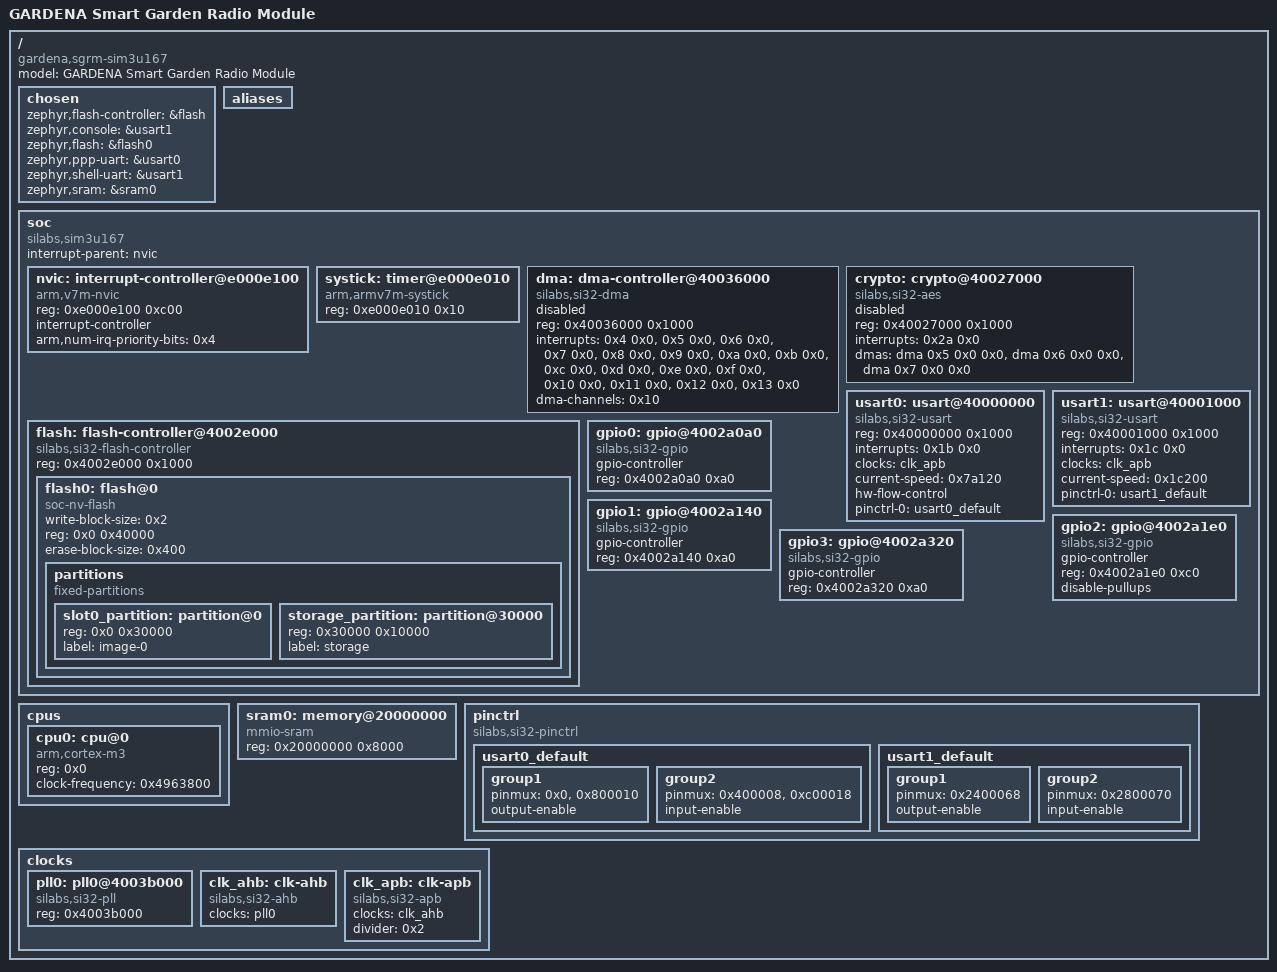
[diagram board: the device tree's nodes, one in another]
/dts-v1/;

/* node '/' defined in zephyr/dts/common/skeleton.dtsi:9 */
/ {
	#address-cells = < 0x1 >;                    /* in zephyr/dts/common/skeleton.dtsi:10 */
	#size-cells = < 0x1 >;                       /* in zephyr/dts/common/skeleton.dtsi:11 */
	model = "GARDENA Smart Garden Radio Module"; /* in zephyr/boards/gardena/sgrm/sgrm.dts:12 */
	compatible = "gardena,sgrm-sim3u167",
	             "silabs,sim3u167",
	             "silabs,sim3u";                 /* in zephyr/boards/gardena/sgrm/sgrm.dts:13 */

	/* node '/chosen' defined in zephyr/dts/common/skeleton.dtsi:13 */
	chosen {
		zephyr,flash-controller = &flash; /* in zephyr/dts/arm/silabs/sim3u.dtsi:13 */
		zephyr,console = &usart1;         /* in zephyr/boards/gardena/sgrm/sgrm.dts:16 */
		zephyr,flash = &flash0;           /* in zephyr/boards/gardena/sgrm/sgrm.dts:17 */
		zephyr,ppp-uart = &usart0;        /* in zephyr/boards/gardena/sgrm/sgrm.dts:18 */
		zephyr,shell-uart = &usart1;      /* in zephyr/boards/gardena/sgrm/sgrm.dts:19 */
		zephyr,sram = &sram0;             /* in zephyr/boards/gardena/sgrm/sgrm.dts:20 */
	};

	/* node '/aliases' defined in zephyr/dts/common/skeleton.dtsi:15 */
	aliases {
	};

	/* node '/soc' defined in zephyr/dts/arm/armv7-m.dtsi:6 */
	soc {
		#address-cells = < 0x1 >;       /* in zephyr/dts/arm/armv7-m.dtsi:7 */
		#size-cells = < 0x1 >;          /* in zephyr/dts/arm/armv7-m.dtsi:8 */
		interrupt-parent = < &nvic >;   /* in zephyr/dts/arm/armv7-m.dtsi:10 */
		ranges;                         /* in zephyr/dts/arm/armv7-m.dtsi:11 */
		compatible = "silabs,sim3u167",
		             "silabs,sim3u",
		             "silabs,sim3",
		             "simple-bus";      /* in zephyr/dts/arm/silabs/sim3u167.dtsi:12 */

		/* node '/soc/interrupt-controller@e000e100' defined in zephyr/dts/arm/armv7-m.dtsi:13 */
		nvic: interrupt-controller@e000e100 {
			#address-cells = < 0x1 >;            /* in zephyr/dts/arm/armv7-m.dtsi:14 */
			compatible = "arm,v7m-nvic";         /* in zephyr/dts/arm/armv7-m.dtsi:15 */
			reg = < 0xe000e100 0xc00 >;          /* in zephyr/dts/arm/armv7-m.dtsi:16 */
			interrupt-controller;                /* in zephyr/dts/arm/armv7-m.dtsi:17 */
			#interrupt-cells = < 0x2 >;          /* in zephyr/dts/arm/armv7-m.dtsi:18 */
			arm,num-irq-priority-bits = < 0x4 >; /* in zephyr/dts/arm/silabs/sim3u.dtsi:147 */
			phandle = < 0x1 >;                   /* in zephyr/dts/arm/armv7-m.dtsi:10 */
		};

		/* node '/soc/timer@e000e010' defined in zephyr/dts/arm/armv7-m.dtsi:21 */
		systick: timer@e000e010 {
			compatible = "arm,armv7m-systick"; /* in zephyr/dts/arm/armv7-m.dtsi:22 */
			reg = < 0xe000e010 0x10 >;         /* in zephyr/dts/arm/armv7-m.dtsi:23 */
		};

		/* node '/soc/dma-controller@40036000' defined in zephyr/dts/arm/silabs/sim3u.dtsi:64 */
		dma: dma-controller@40036000 {
			compatible = "silabs,si32-dma"; /* in zephyr/dts/arm/silabs/sim3u.dtsi:65 */
			reg = < 0x40036000 0x1000 >;    /* in zephyr/dts/arm/silabs/sim3u.dtsi:66 */
			interrupts = < 0x4 0x0 >,
			             < 0x5 0x0 >,
			             < 0x6 0x0 >,
			             < 0x7 0x0 >,
			             < 0x8 0x0 >,
			             < 0x9 0x0 >,
			             < 0xa 0x0 >,
			             < 0xb 0x0 >,
			             < 0xc 0x0 >,
			             < 0xd 0x0 >,
			             < 0xe 0x0 >,
			             < 0xf 0x0 >,
			             < 0x10 0x0 >,
			             < 0x11 0x0 >,
			             < 0x12 0x0 >,
			             < 0x13 0x0 >;      /* in zephyr/dts/arm/silabs/sim3u.dtsi:67 */
			dma-channels = < 0x10 >;        /* in zephyr/dts/arm/silabs/sim3u.dtsi:71 */
			#dma-cells = < 0x3 >;           /* in zephyr/dts/arm/silabs/sim3u.dtsi:72 */
			status = "disabled";            /* in zephyr/dts/arm/silabs/sim3u.dtsi:73 */
			phandle = < 0x2 >;              /* in zephyr/dts/arm/silabs/sim3u.dtsi:80 */
		};

		/* node '/soc/crypto@40027000' defined in zephyr/dts/arm/silabs/sim3u.dtsi:76 */
		crypto: crypto@40027000 {
			compatible = "silabs,si32-aes"; /* in zephyr/dts/arm/silabs/sim3u.dtsi:77 */
			reg = < 0x40027000 0x1000 >;    /* in zephyr/dts/arm/silabs/sim3u.dtsi:78 */
			interrupts = < 0x2a 0x0 >;      /* in zephyr/dts/arm/silabs/sim3u.dtsi:79 */
			dmas = < &dma 0x5 0x0 0x0 >,
			       < &dma 0x6 0x0 0x0 >,
			       < &dma 0x7 0x0 0x0 >;    /* in zephyr/dts/arm/silabs/sim3u.dtsi:80 */
			dma-names = "tx",
			            "rx",
			            "xor";              /* in zephyr/dts/arm/silabs/sim3u.dtsi:83 */
			status = "disabled";            /* in zephyr/dts/arm/silabs/sim3u.dtsi:84 */
		};

		/* node '/soc/flash-controller@4002e000' defined in zephyr/dts/arm/silabs/sim3u.dtsi:87 */
		flash: flash-controller@4002e000 {
			compatible = "silabs,si32-flash-controller"; /* in zephyr/dts/arm/silabs/sim3u.dtsi:88 */
			reg = < 0x4002e000 0x1000 >;                 /* in zephyr/dts/arm/silabs/sim3u.dtsi:89 */
			#address-cells = < 0x1 >;                    /* in zephyr/dts/arm/silabs/sim3u.dtsi:91 */
			#size-cells = < 0x1 >;                       /* in zephyr/dts/arm/silabs/sim3u.dtsi:92 */

			/* node '/soc/flash-controller@4002e000/flash@0' defined in zephyr/dts/arm/silabs/sim3u.dtsi:94 */
			flash0: flash@0 {
				compatible = "soc-nv-flash";  /* in zephyr/dts/arm/silabs/sim3u.dtsi:95 */
				write-block-size = < 0x2 >;   /* in zephyr/dts/arm/silabs/sim3u.dtsi:96 */
				reg = < 0x0 0x40000 >;        /* in zephyr/dts/arm/silabs/sim3u167.dtsi:17 */
				erase-block-size = < 0x400 >; /* in zephyr/dts/arm/silabs/sim3u167.dtsi:18 */
				status = "okay";              /* in zephyr/boards/gardena/sgrm/sgrm.dts:75 */

				/* node '/soc/flash-controller@4002e000/flash@0/partitions' defined in zephyr/boards/gardena/sgrm/sgrm.dts:77 */
				partitions {
					compatible = "fixed-partitions"; /* in zephyr/boards/gardena/sgrm/sgrm.dts:78 */
					#address-cells = < 0x1 >;        /* in zephyr/boards/gardena/sgrm/sgrm.dts:79 */
					#size-cells = < 0x1 >;           /* in zephyr/boards/gardena/sgrm/sgrm.dts:80 */

					/* node '/soc/flash-controller@4002e000/flash@0/partitions/partition@0' defined in zephyr/boards/gardena/sgrm/sgrm.dts:82 */
					slot0_partition: partition@0 {
						reg = < 0x0 0x30000 >; /* in zephyr/boards/gardena/sgrm/sgrm.dts:83 */
						label = "image-0";     /* in zephyr/boards/gardena/sgrm/sgrm.dts:84 */
					};

					/* node '/soc/flash-controller@4002e000/flash@0/partitions/partition@30000' defined in zephyr/boards/gardena/sgrm/sgrm.dts:87 */
					storage_partition: partition@30000 {
						reg = < 0x30000 0x10000 >; /* in zephyr/boards/gardena/sgrm/sgrm.dts:88 */
						label = "storage";         /* in zephyr/boards/gardena/sgrm/sgrm.dts:89 */
					};
				};
			};
		};

		/* node '/soc/usart@40000000' defined in zephyr/dts/arm/silabs/sim3u.dtsi:100 */
		usart0: usart@40000000 {
			compatible = "silabs,si32-usart"; /* in zephyr/dts/arm/silabs/sim3u.dtsi:101 */
			reg = < 0x40000000 0x1000 >;      /* in zephyr/dts/arm/silabs/sim3u.dtsi:102 */
			interrupts = < 0x1b 0x0 >;        /* in zephyr/dts/arm/silabs/sim3u.dtsi:103 */
			clocks = < &clk_apb >;            /* in zephyr/dts/arm/silabs/sim3u.dtsi:104 */
			current-speed = < 0x7a120 >;      /* in zephyr/boards/gardena/sgrm/sgrm.dts:43 */
			hw-flow-control;                  /* in zephyr/boards/gardena/sgrm/sgrm.dts:44 */
			pinctrl-0 = < &usart0_default >;  /* in zephyr/boards/gardena/sgrm/sgrm.dts:45 */
			pinctrl-names = "default";        /* in zephyr/boards/gardena/sgrm/sgrm.dts:46 */
			status = "okay";                  /* in zephyr/boards/gardena/sgrm/sgrm.dts:47 */
		};

		/* node '/soc/usart@40001000' defined in zephyr/dts/arm/silabs/sim3u.dtsi:108 */
		usart1: usart@40001000 {
			compatible = "silabs,si32-usart"; /* in zephyr/dts/arm/silabs/sim3u.dtsi:109 */
			reg = < 0x40001000 0x1000 >;      /* in zephyr/dts/arm/silabs/sim3u.dtsi:110 */
			interrupts = < 0x1c 0x0 >;        /* in zephyr/dts/arm/silabs/sim3u.dtsi:111 */
			clocks = < &clk_apb >;            /* in zephyr/dts/arm/silabs/sim3u.dtsi:112 */
			current-speed = < 0x1c200 >;      /* in zephyr/boards/gardena/sgrm/sgrm.dts:51 */
			pinctrl-0 = < &usart1_default >;  /* in zephyr/boards/gardena/sgrm/sgrm.dts:52 */
			pinctrl-names = "default";        /* in zephyr/boards/gardena/sgrm/sgrm.dts:53 */
			status = "okay";                  /* in zephyr/boards/gardena/sgrm/sgrm.dts:54 */
		};

		/* node '/soc/gpio@4002a0a0' defined in zephyr/dts/arm/silabs/sim3u.dtsi:116 */
		gpio0: gpio@4002a0a0 {
			compatible = "silabs,si32-gpio"; /* in zephyr/dts/arm/silabs/sim3u.dtsi:117 */
			gpio-controller;                 /* in zephyr/dts/arm/silabs/sim3u.dtsi:118 */
			#gpio-cells = < 0x2 >;           /* in zephyr/dts/arm/silabs/sim3u.dtsi:119 */
			reg = < 0x4002a0a0 0xa0 >;       /* in zephyr/dts/arm/silabs/sim3u.dtsi:120 */
			status = "okay";                 /* in zephyr/boards/gardena/sgrm/sgrm.dts:58 */
		};

		/* node '/soc/gpio@4002a140' defined in zephyr/dts/arm/silabs/sim3u.dtsi:123 */
		gpio1: gpio@4002a140 {
			compatible = "silabs,si32-gpio"; /* in zephyr/dts/arm/silabs/sim3u.dtsi:124 */
			gpio-controller;                 /* in zephyr/dts/arm/silabs/sim3u.dtsi:125 */
			#gpio-cells = < 0x2 >;           /* in zephyr/dts/arm/silabs/sim3u.dtsi:126 */
			reg = < 0x4002a140 0xa0 >;       /* in zephyr/dts/arm/silabs/sim3u.dtsi:127 */
			status = "okay";                 /* in zephyr/boards/gardena/sgrm/sgrm.dts:62 */
		};

		/* node '/soc/gpio@4002a1e0' defined in zephyr/dts/arm/silabs/sim3u.dtsi:130 */
		gpio2: gpio@4002a1e0 {
			compatible = "silabs,si32-gpio"; /* in zephyr/dts/arm/silabs/sim3u.dtsi:131 */
			gpio-controller;                 /* in zephyr/dts/arm/silabs/sim3u.dtsi:132 */
			#gpio-cells = < 0x2 >;           /* in zephyr/dts/arm/silabs/sim3u.dtsi:133 */
			reg = < 0x4002a1e0 0xc0 >;       /* in zephyr/dts/arm/silabs/sim3u.dtsi:134 */
			disable-pullups;                 /* in zephyr/boards/gardena/sgrm/sgrm.dts:66 */
			status = "okay";                 /* in zephyr/boards/gardena/sgrm/sgrm.dts:67 */
		};

		/* node '/soc/gpio@4002a320' defined in zephyr/dts/arm/silabs/sim3u.dtsi:137 */
		gpio3: gpio@4002a320 {
			compatible = "silabs,si32-gpio"; /* in zephyr/dts/arm/silabs/sim3u.dtsi:138 */
			gpio-controller;                 /* in zephyr/dts/arm/silabs/sim3u.dtsi:139 */
			#gpio-cells = < 0x2 >;           /* in zephyr/dts/arm/silabs/sim3u.dtsi:140 */
			reg = < 0x4002a320 0xa0 >;       /* in zephyr/dts/arm/silabs/sim3u.dtsi:141 */
			status = "okay";                 /* in zephyr/boards/gardena/sgrm/sgrm.dts:71 */
		};
	};

	/* node '/cpus' defined in zephyr/dts/arm/silabs/sim3u.dtsi:16 */
	cpus {
		#address-cells = < 0x1 >; /* in zephyr/dts/arm/silabs/sim3u.dtsi:17 */
		#size-cells = < 0x0 >;    /* in zephyr/dts/arm/silabs/sim3u.dtsi:18 */

		/* node '/cpus/cpu@0' defined in zephyr/dts/arm/silabs/sim3u.dtsi:20 */
		cpu0: cpu@0 {
			compatible = "arm,cortex-m3";    /* in zephyr/dts/arm/silabs/sim3u.dtsi:21 */
			device_type = "cpu";             /* in zephyr/dts/arm/silabs/sim3u.dtsi:22 */
			reg = < 0x0 >;                   /* in zephyr/dts/arm/silabs/sim3u.dtsi:24 */
			clock-frequency = < 0x4963800 >; /* in zephyr/boards/gardena/sgrm/sgrm.dts:25 */
		};
	};

	/* node '/memory@20000000' defined in zephyr/dts/arm/silabs/sim3u.dtsi:28 */
	sram0: memory@20000000 {
		compatible = "mmio-sram";    /* in zephyr/dts/arm/silabs/sim3u.dtsi:29 */
		reg = < 0x20000000 0x8000 >; /* in zephyr/dts/arm/silabs/sim3u167.dtsi:22 */
	};

	/* node '/pinctrl' defined in zephyr/dts/arm/silabs/sim3u.dtsi:32 */
	pinctrl: pinctrl {
		compatible = "silabs,si32-pinctrl"; /* in zephyr/dts/arm/silabs/sim3u.dtsi:33 */
		status = "okay";                    /* in zephyr/dts/arm/silabs/sim3u.dtsi:34 */

		/* node '/pinctrl/usart0_default' defined in zephyr/boards/gardena/sgrm/sgrm-pinctrl.dtsi:10 */
		usart0_default: usart0_default {
			phandle = < 0x4 >; /* in zephyr/boards/gardena/sgrm/sgrm.dts:45 */

			/* node '/pinctrl/usart0_default/group1' defined in zephyr/boards/gardena/sgrm/sgrm-pinctrl.dtsi:11 */
			group1 {
				pinmux = < 0x0 >,
				         < 0x800010 >; /* in zephyr/boards/gardena/sgrm/sgrm-pinctrl.dtsi:12 */
				output-enable;         /* in zephyr/boards/gardena/sgrm/sgrm-pinctrl.dtsi:14 */
			};

			/* node '/pinctrl/usart0_default/group2' defined in zephyr/boards/gardena/sgrm/sgrm-pinctrl.dtsi:17 */
			group2 {
				pinmux = < 0x400008 >,
				         < 0xc00018 >; /* in zephyr/boards/gardena/sgrm/sgrm-pinctrl.dtsi:18 */
				input-enable;          /* in zephyr/boards/gardena/sgrm/sgrm-pinctrl.dtsi:20 */
			};
		};

		/* node '/pinctrl/usart1_default' defined in zephyr/boards/gardena/sgrm/sgrm-pinctrl.dtsi:24 */
		usart1_default: usart1_default {
			phandle = < 0x5 >; /* in zephyr/boards/gardena/sgrm/sgrm.dts:52 */

			/* node '/pinctrl/usart1_default/group1' defined in zephyr/boards/gardena/sgrm/sgrm-pinctrl.dtsi:25 */
			group1 {
				pinmux = < 0x2400068 >; /* in zephyr/boards/gardena/sgrm/sgrm-pinctrl.dtsi:26 */
				output-enable;          /* in zephyr/boards/gardena/sgrm/sgrm-pinctrl.dtsi:27 */
			};

			/* node '/pinctrl/usart1_default/group2' defined in zephyr/boards/gardena/sgrm/sgrm-pinctrl.dtsi:30 */
			group2 {
				pinmux = < 0x2800070 >; /* in zephyr/boards/gardena/sgrm/sgrm-pinctrl.dtsi:31 */
				input-enable;           /* in zephyr/boards/gardena/sgrm/sgrm-pinctrl.dtsi:32 */
			};
		};
	};

	/* node '/clocks' defined in zephyr/dts/arm/silabs/sim3u.dtsi:37 */
	clocks {
		#address-cells = < 0x1 >; /* in zephyr/dts/arm/silabs/sim3u.dtsi:38 */
		#size-cells = < 0x0 >;    /* in zephyr/dts/arm/silabs/sim3u.dtsi:39 */

		/* node '/clocks/pll0@4003b000' defined in zephyr/dts/arm/silabs/sim3u.dtsi:41 */
		pll0: pll0@4003b000 {
			compatible = "silabs,si32-pll"; /* in zephyr/dts/arm/silabs/sim3u.dtsi:42 */
			#clock-cells = < 0x0 >;         /* in zephyr/dts/arm/silabs/sim3u.dtsi:43 */
			reg = < 0x4003b000 >;           /* in zephyr/dts/arm/silabs/sim3u.dtsi:44 */
			status = "okay";                /* in zephyr/boards/gardena/sgrm/sgrm.dts:29 */
			phandle = < 0x6 >;              /* in zephyr/boards/gardena/sgrm/sgrm.dts:33 */
		};

		/* node '/clocks/clk-ahb' defined in zephyr/dts/arm/silabs/sim3u.dtsi:48 */
		clk_ahb: clk-ahb {
			compatible = "silabs,si32-ahb"; /* in zephyr/dts/arm/silabs/sim3u.dtsi:49 */
			#clock-cells = < 0x0 >;         /* in zephyr/dts/arm/silabs/sim3u.dtsi:50 */
			clocks = < &pll0 >;             /* in zephyr/boards/gardena/sgrm/sgrm.dts:33 */
			status = "okay";                /* in zephyr/boards/gardena/sgrm/sgrm.dts:34 */
			phandle = < 0x7 >;              /* in zephyr/dts/arm/silabs/sim3u.dtsi:58 */
		};

		/* node '/clocks/clk-apb' defined in zephyr/dts/arm/silabs/sim3u.dtsi:54 */
		clk_apb: clk-apb {
			compatible = "silabs,si32-apb"; /* in zephyr/dts/arm/silabs/sim3u.dtsi:55 */
			#clock-cells = < 0x0 >;         /* in zephyr/dts/arm/silabs/sim3u.dtsi:56 */
			clocks = < &clk_ahb >;          /* in zephyr/dts/arm/silabs/sim3u.dtsi:58 */
			divider = < 0x2 >;              /* in zephyr/boards/gardena/sgrm/sgrm.dts:38 */
			status = "okay";                /* in zephyr/boards/gardena/sgrm/sgrm.dts:39 */
			phandle = < 0x3 >;              /* in zephyr/dts/arm/silabs/sim3u.dtsi:104 */
		};
	};
};
